# ATtiny88 register map
Vendor: Atmel; File version: 1.0
CPU: other r0p0, little endian, no MPU, no FPU, 4 interrupt priority bits
Registers are 8-bit, read-write, reset 0x0 unless marked. A register's access mark holds for its fields unless they carry their own. Offsets are from the block's base; lines under a group give offsets from that group; [hi:lo] are bit positions; {n}, {i} and the like mark numbered series; 'fields as' and 'values as' point back to an identical list; <NAME> marks a mode.

## Memory map
0x00800023 PORTB size 0x3 — I/O Port
0x00800026 PORTC size 0x3 — I/O Port
0x00800029 PORTD size 0x3 — I/O Port
0x0080002C PORTA size 0x3 — I/O Port
0x00800032 CPU blocks up to offset 0x35 — CPU Registers
0x00800035 TC0 blocks up to offset 0x3A — Timer/Counter, 8-bit
0x00800036 TC1 blocks up to offset 0x56 — Timer/Counter, 16-bit
0x0080003B EXINT blocks up to offset 0x33 — External Interrupts
0x0080003F EEPROM size 0x3
0x0080004C SPI size 0x3 — Serial Peripheral Interface
0x00800050 AC blocks up to offset 0x30 — Analog Comparator
0x00800060 WDT size 0x1 — Watchdog Timer
0x00800078 ADC blocks up to offset 0x8 — Analog-to-Digital Converter
0x008000B8 TWI size 0x7 — Two Wire Serial Interface

## Interrupts
0 RESET (CPU) — External Pin, Power-on Reset, Brown-out Reset and Watchdog Reset
1 INT0 (CPU) — External Interrupt Request 0
2 INT1 (CPU) — External Interrupt Request 1
3 PCINT0 (CPU) — Pin Change Interrupt Request 0
4 PCINT1 (CPU) — Pin Change Interrupt Request 1
5 PCINT2 (CPU) — Pin Change Interrupt Request 2
6 PCINT3 (CPU) — Pin Change Interrupt Request 3
7 WDT (CPU) — Watchdog Time-out Interrupt
8 TIMER1_CAPT (CPU) — Timer/Counter1 Capture Event
9 TIMER1_COMPA (CPU) — Timer/Counter1 Compare Match A
10 TIMER1_COMPB (CPU) — Timer/Counter1 Compare Match B
11 TIMER1_OVF (CPU) — Timer/Counter1 Overflow
12 TIMER0_COMPA (CPU) — TimerCounter0 Compare Match A
13 TIMER0_COMPB (CPU) — TimerCounter0 Compare Match B
14 TIMER0_OVF (CPU) — Timer/Counter0 Overflow
15 SPI_STC (CPU) — SPI Serial Transfer Complete
16 ADC (CPU) — ADC Conversion Complete
17 EE_RDY (CPU) — EEPROM Ready
18 ANALOG_COMP (CPU) — Analog Comparator
19 TWI (CPU) — Two-wire Serial Interface

## AC — Analog Comparator
Base 0x00800050
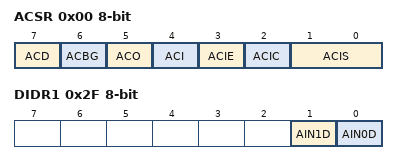
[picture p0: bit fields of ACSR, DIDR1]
0x00 ACSR — Analog Comparator Control And Status Register (read-only for debugger)
  [7] ACD — Analog Comparator Disable
  [6] ACBG — Analog Comparator Bandgap Select
  [5] ACO — Analog Compare Output
  [4] ACI — Analog Comparator Interrupt Flag
  [3] ACIE — Analog Comparator Interrupt Enable
  [2] ACIC — Analog Comparator Input Capture Enable
  [1:0] ACIS — Analog Comparator Interrupt Mode Select bits
    0=INTERRUPT_ON_TOGGLE; 2=INTERRUPT_ON_FALLING_EDGE; 3=INTERRUPT_ON_RISING_EDGE
0x2F DIDR1 — Digital Input Disable Register 1
  [1] AIN1D — AIN1 Digital Input Disable
  [0] AIN0D — AIN0 Digital Input Disable

## ADC — Analog-to-Digital Converter
Base 0x00800078
0x00 ADC 16-bit (reset mask 0xFF) — ADC Data Register Bytes
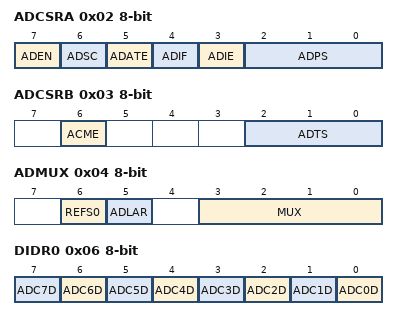
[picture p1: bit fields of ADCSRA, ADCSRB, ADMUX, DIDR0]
0x02 ADCSRA — The ADC Control and Status register A
  [7] ADEN — ADC Enable
  [6] ADSC — ADC Start Conversion
  [5] ADATE — ADC Auto Trigger Enable
  [4] ADIF — ADC Interrupt Flag
  [3] ADIE — ADC Interrupt Enable
  [2:0] ADPS — ADC Prescaler Select Bits
    1=2; 2=4; 3=8; 4=16; 5=32; 6=64; 7=128
0x03 ADCSRB — The ADC Control and Status register B
  [6] ACME
  [2:0] ADTS — ADC Auto Trigger Source bits
    0=FREE_RUNNING_MODE; 1=ANALOG_COMPARATOR; 2=EXTERNAL_INTERRUPT_REQUEST_0; 3=TIMER_COUNTER0_COMPARE_MATCH_A; 4=TIMER_COUNTER0_OVERFLOW; 5=TIMER_COUNTER1_COMPARE_MATCH_B; 6=TIMER_COUNTER1_OVERFLOW; 7=TIMER_COUNTER1_CAPTURE_EVENT
0x04 ADMUX — The ADC multiplexer Selection Register
  [6] REFS0 — Reference Selection Bit 0
    0=INTERNAL_1_1V_VOLTAGE_REFERENCE; 1=AVCC_REFERENCE
  [5] ADLAR — Left Adjust Result
  [3:0] MUX — Analog Channel and Gain Selection Bits
0x06 DIDR0 — Digital Input Disable Register 0
  [n] ADC{n}D (n=0..7)
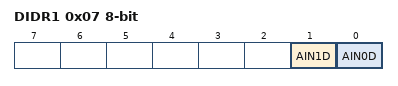
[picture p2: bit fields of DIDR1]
0x07 DIDR1 — Digital Input Disable Register 1
  [1] AIN1D, [0] AIN0D
